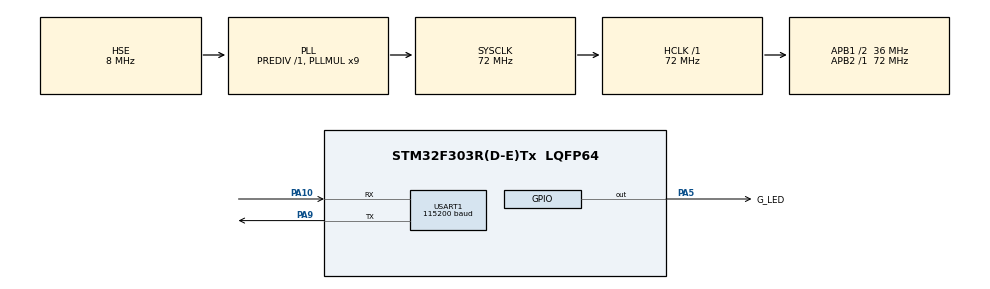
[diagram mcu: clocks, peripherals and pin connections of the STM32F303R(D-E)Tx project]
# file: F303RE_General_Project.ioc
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Mcu.Family=STM32F3
Mcu.Name=STM32F303R(D-E)Tx
Mcu.Package=LQFP64
NVIC.PriorityGroup=NVIC_PRIORITYGROUP_4
PA10.GPIO_PuPd=GPIO_PULLUP
PA10.Mode=Asynchronous
PA10.Signal=USART1_RX
PA5.GPIO_Label=G_LED
PA5.Signal=GPIO_Output
PA9.GPIO_PuPd=GPIO_PULLUP
PA9.Mode=Asynchronous
PA9.Signal=USART1_TX
PF0-OSC_IN.Mode=HSE-External-Oscillator
PF0-OSC_IN.Signal=RCC_OSC_IN
PF1-OSC_OUT.Mode=HSE-External-Oscillator
PF1-OSC_OUT.Signal=RCC_OSC_OUT
ProjectManager.HeapSize=0x200
ProjectManager.StackSize=0x400
ProjectManager.TargetToolchain=STM32CubeIDE
RCC.AHBFreq_Value=72000000
RCC.APB1CLKDivider=RCC_HCLK_DIV2
RCC.APB1Freq_Value=36000000
RCC.APB1TimFreq_Value=72000000
RCC.APB2Freq_Value=72000000
RCC.APB2TimFreq_Value=72000000
RCC.CortexFreq_Value=72000000
RCC.HCLKFreq_Value=72000000
RCC.HSE_VALUE=8000000
RCC.HSI_VALUE=8000000
RCC.LSE_VALUE=32768
RCC.PLLMUL=RCC_PLL_MUL9
RCC.PLLSourceVirtual=RCC_PLLSOURCE_HSE
RCC.SYSCLKFreq_VALUE=72000000
RCC.SYSCLKSourceVirtual=RCC_SYSCLKSOURCE_PLLCLK
RCC.USBFreq_Value=72000000
USART1.BaudRate=115200
USART1.Parity=PARITY_EVEN
USART1.VirtualMode-Asynchronous=VM_ASYNC
USART1.WordLength=WORDLENGTH_9B
board=custom

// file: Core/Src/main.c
/* USER CODE BEGIN Header */
/**
 ******************************************************************************
 * @file           : main.c
 * @brief          : Main program body
 ******************************************************************************
 * @attention
 *
 * Copyright (c) 2025 STMicroelectronics.
 * All rights reserved.
 *
 * This software is licensed under terms that can be found in the LICENSE file
 * in the root directory of this software component.
 * If no LICENSE file comes with this software, it is provided AS-IS.
 *
 ******************************************************************************
 */
/* USER CODE END Header */
#include "main.h"

/* USER CODE BEGIN Includes */
#include"string.h"
#include"math.h"
#include"firmware.h"
#include <stdint.h>
/* USER CODE END Includes */

/* USER CODE BEGIN PTD */
#define TARGET_FLASH_ADDR 0x08000000
#define BIN_SIZE          8084     // Update with your actual .bin size

#define ACK  0x79
#define NACK 0x1F

#define STM32_FLASH_START_ADDR 0x08000000
#define MAX_CHUNK_SIZE 256
/* USER CODE END PTD */

/* USER CODE BEGIN PD */
#define SCB_AIRCR (*(volatile uint32_t*)0xE000ED0C)  // Define AIRCR register address
#define VECTKEY   (0x05FA << 16)                     // VECTKEY value to unlock AIRCR
#define SYSRESETREQ (1 << 2)                         // SYSRESETREQ bit position
/* USER CODE END PD */

UART_HandleTypeDef huart1;

/* USER CODE BEGIN PV */
uint8_t status=0;
uint8_t commands[256] = {0};
/* USER CODE END PV */

void SystemClock_Config(void);
static void MX_GPIO_Init(void);
static void MX_USART1_UART_Init(void);

/* USER CODE BEGIN 0 */
// Utility: Send command and get ACK
#include "stm32f3xx_hal.h"
#include <stdio.h>

extern UART_HandleTypeDef huart1; // Your UART instance

#define ACK   0x79
#define NACK  0x1F

HAL_StatusTypeDef send_command(uint8_t cmd) {
	uint8_t packet[2] = {cmd, (uint8_t)(cmd ^ 0xFF)};
	HAL_UART_Transmit(&huart1, packet, 2, HAL_MAX_DELAY);
	uint8_t ack;
	HAL_UART_Receive(&huart1, &ack, 1, HAL_MAX_DELAY);
	return (ack == ACK) ? HAL_OK : HAL_ERROR;
}

HAL_StatusTypeDef send_get_command(void) {
	uint8_t cmd[2] = {0x00, 0xFF}; // Get command and its XOR
	HAL_StatusTypeDef status;

	// 1. Send the Get command
	status = HAL_UART_Transmit(&huart1, cmd, 2, HAL_MAX_DELAY);
	//if (status != HAL_OK) return status;

	// 2. Receive the first ACK
	uint8_t ack;
	status = HAL_UART_Receive(&huart1, &ack, 1, HAL_MAX_DELAY);
	//    if (status != HAL_OK || ack != ACK) {
	//        return HAL_ERROR;
	//    }

	// 3. Receive N (number of command bytes - 1)
	uint8_t n;
	status = HAL_UART_Receive(&huart1, &n, 1, HAL_MAX_DELAY);
	//if (status != HAL_OK) return status;

	// 4. Receive bootloader version
	uint8_t version;
	status = HAL_UART_Receive(&huart1, &version, 1, HAL_MAX_DELAY);
	//if (status != HAL_OK) return status;

	// 5. Receive N+1 command codes
	memset(commands,0,256);
	uint8_t num_cmds = n ;
	//uint8_t commands[256] = {0}; // just in case, enough size
	status = HAL_UART_Receive(&huart1, commands, num_cmds, HAL_MAX_DELAY);
	//if (status != HAL_OK) return status;

	// 6. Final ACK
	uint8_t final_ack;
	status = HAL_UART_Receive(&huart1, &final_ack, 1, HAL_MAX_DELAY);
	if (status != HAL_OK || final_ack != ACK) {
		return HAL_ERROR;
	}
	return HAL_OK;
}

// Utility: Send 32-bit address + checksum
HAL_StatusTypeDef send_address(uint32_t address) {
	uint8_t addr_buf[5];
	addr_buf[0] = (address >> 24) & 0xFF;
	addr_buf[1] = (address >> 16) & 0xFF;
	addr_buf[2] = (address >> 8) & 0xFF;
	addr_buf[3] = address & 0xFF;
	addr_buf[4] = addr_buf[0] ^ addr_buf[1] ^ addr_buf[2] ^ addr_buf[3];

	HAL_UART_Transmit(&huart1, addr_buf, 5, HAL_MAX_DELAY);

	uint8_t ack;
	if (HAL_UART_Receive(&huart1, &ack, 1, HAL_MAX_DELAY) != HAL_OK)
		return HAL_ERROR;

	return (ack == ACK) ? HAL_OK : HAL_ERROR;
}

// Utility: Write data chunk (max 256 bytes)
HAL_StatusTypeDef send_data_chunk(const uint8_t *data, uint32_t length) {
	if (length == 0 || length > 256) return HAL_ERROR;

	uint8_t buffer[1 + 256 + 1];  // len + data + checksum
	buffer[0] = length - 1;

	uint8_t checksum = buffer[0];
	for (uint32_t i = 0; i < length; i++) {
		buffer[1 + i] = data[i];
		checksum ^= data[i];
	}
	buffer[1 + length] = checksum;

	HAL_UART_Transmit(&huart1, buffer, length + 2, HAL_MAX_DELAY);

	uint8_t ack;
	if (HAL_UART_Receive(&huart1, &ack, 1, HAL_MAX_DELAY) != HAL_OK)
		return HAL_ERROR;

	return (ack == ACK) ? HAL_OK : HAL_ERROR;
}

void send_firmware_to_target(void) {
	uint32_t offset = 0;
	uint32_t current_address = STM32_FLASH_START_ADDR;

	while (offset < firmware_size) {
		uint32_t chunk_size = ((firmware_size - offset) > MAX_CHUNK_SIZE)
                            		  ? MAX_CHUNK_SIZE
                            				  : (firmware_size - offset);

		if (send_command(0x31) != HAL_OK) {
			while(1);
		}

		if (send_address(current_address) != HAL_OK) {
			while(1);
		}

		if (send_data_chunk(&firmware_bin[offset], chunk_size) != HAL_OK) {
			while(1);
		}

		current_address += chunk_size;
		offset += chunk_size;

		HAL_Delay(10);  // Optional: small delay to ensure target is ready
	}

}
/* USER CODE END 0 */

int main(void)
{

  /* MCU Configuration--------------------------------------------------------*/

  /* Reset of all peripherals, Initializes the Flash interface and the Systick. */
  HAL_Init();

  /* Configure the system clock */
  SystemClock_Config();

  /* Initialize all configured peripherals */
  MX_GPIO_Init();
  MX_USART1_UART_Init();

  /* Infinite loop */
  /* USER CODE BEGIN WHILE */
	HAL_Delay(250);

	status=send_command(0x7f);
	if(status==1)
	{
		while(1);
	}
	else
	{
		status=send_get_command();
	}

	HAL_Delay(1);
	status=send_command(0x44);
	if(status==1)
	{
		while(1);
	}
	else
	{
		uint8_t ack;
		HAL_Delay(1);
		uint8_t global_erase[3] = {0xFF, 0xFF, 0x00};
		HAL_UART_Transmit(&huart1, global_erase, 3, HAL_MAX_DELAY);
		HAL_UART_Receive(&huart1, &ack, 1, HAL_MAX_DELAY);
		if (ack != 0x79)
		{
			status=1;
		}
	}

	if(status==1)
	{
		while(1);
	}
	else
	{
       send_firmware_to_target();
	}

	HAL_GPIO_WritePin(G_LED_GPIO_Port, G_LED_Pin, 0);

	while (1)
	{
    /* USER CODE END WHILE */

    /* USER CODE BEGIN 3 */
		HAL_GPIO_TogglePin(G_LED_GPIO_Port, G_LED_Pin);
		HAL_Delay(1000);
	}
  /* USER CODE END 3 */
}

void SystemClock_Config(void)
{
  RCC_OscInitTypeDef RCC_OscInitStruct = {0};
  RCC_ClkInitTypeDef RCC_ClkInitStruct = {0};
  RCC_PeriphCLKInitTypeDef PeriphClkInit = {0};

  /** Initializes the RCC Oscillators according to the specified parameters
  * in the RCC_OscInitTypeDef structure.
  */
  RCC_OscInitStruct.OscillatorType = RCC_OSCILLATORTYPE_HSE;
  RCC_OscInitStruct.HSEState = RCC_HSE_ON;
  RCC_OscInitStruct.HSIState = RCC_HSI_ON;
  RCC_OscInitStruct.PLL.PLLState = RCC_PLL_ON;
  RCC_OscInitStruct.PLL.PLLSource = RCC_PLLSOURCE_HSE;
  RCC_OscInitStruct.PLL.PLLMUL = RCC_PLL_MUL9;
  RCC_OscInitStruct.PLL.PREDIV = RCC_PREDIV_DIV1;
  if (HAL_RCC_OscConfig(&RCC_OscInitStruct) != HAL_OK)
  {
    Error_Handler();
  }

  /** Initializes the CPU, AHB and APB buses clocks
  */
  RCC_ClkInitStruct.ClockType = RCC_CLOCKTYPE_HCLK|RCC_CLOCKTYPE_SYSCLK
                              |RCC_CLOCKTYPE_PCLK1|RCC_CLOCKTYPE_PCLK2;
  RCC_ClkInitStruct.SYSCLKSource = RCC_SYSCLKSOURCE_PLLCLK;
  RCC_ClkInitStruct.AHBCLKDivider = RCC_SYSCLK_DIV1;
  RCC_ClkInitStruct.APB1CLKDivider = RCC_HCLK_DIV2;
  RCC_ClkInitStruct.APB2CLKDivider = RCC_HCLK_DIV1;

  if (HAL_RCC_ClockConfig(&RCC_ClkInitStruct, FLASH_LATENCY_2) != HAL_OK)
  {
    Error_Handler();
  }
  PeriphClkInit.PeriphClockSelection = RCC_PERIPHCLK_USART1;
  PeriphClkInit.Usart1ClockSelection = RCC_USART1CLKSOURCE_PCLK2;
  if (HAL_RCCEx_PeriphCLKConfig(&PeriphClkInit) != HAL_OK)
  {
    Error_Handler();
  }
}

static void MX_USART1_UART_Init(void)
{

  huart1.Instance = USART1;
  huart1.Init.BaudRate = 115200;
  huart1.Init.WordLength = UART_WORDLENGTH_9B;
  huart1.Init.StopBits = UART_STOPBITS_1;
  huart1.Init.Parity = UART_PARITY_EVEN;
  huart1.Init.Mode = UART_MODE_TX_RX;
  huart1.Init.HwFlowCtl = UART_HWCONTROL_NONE;
  huart1.Init.OverSampling = UART_OVERSAMPLING_16;
  huart1.Init.OneBitSampling = UART_ONE_BIT_SAMPLE_DISABLE;
  huart1.AdvancedInit.AdvFeatureInit = UART_ADVFEATURE_NO_INIT;
  if (HAL_UART_Init(&huart1) != HAL_OK)
  {
    Error_Handler();
  }

}

static void MX_GPIO_Init(void)
{
  GPIO_InitTypeDef GPIO_InitStruct = {0};

  /* GPIO Ports Clock Enable */
  __HAL_RCC_GPIOF_CLK_ENABLE();
  __HAL_RCC_GPIOA_CLK_ENABLE();

  /*Configure GPIO pin Output Level */
  HAL_GPIO_WritePin(G_LED_GPIO_Port, G_LED_Pin, GPIO_PIN_RESET);

  /*Configure GPIO pin : G_LED_Pin */
  GPIO_InitStruct.Pin = G_LED_Pin;
  GPIO_InitStruct.Mode = GPIO_MODE_OUTPUT_PP;
  GPIO_InitStruct.Pull = GPIO_NOPULL;
  GPIO_InitStruct.Speed = GPIO_SPEED_FREQ_LOW;
  HAL_GPIO_Init(G_LED_GPIO_Port, &GPIO_InitStruct);

}

void Error_Handler(void)
{
	__disable_irq();
	while (1)
	{
	}
}
